CM_ "AUTOGENERATED FILE, DO NOT EDIT"

CM_ "bmw_e39_540i.dbc starts here"
Skip to content
Search or jump to…

Pull requests
Issues
Marketplace
Explore

@killinen
killinen
/
opendbc
forked from Sebastian9191/opendbc
0
0518
 Code
 Pull requests 0 Actions
 Projects 0
 Wiki
 Security 0
 Insights
 Settings
opendbc/BMW_E39.dbc
@killinen killinen OpenDBC updates
cff6fd5 2 days ago
@killinen@Sebastian9191
145 lines (122 sloc)  4.56 KB

VERSION ""

NS_ :

BS_:

BU_: XXX

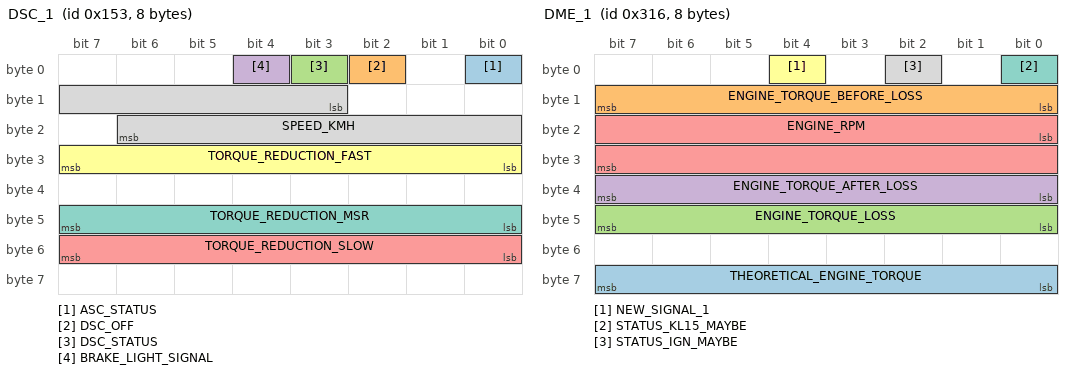
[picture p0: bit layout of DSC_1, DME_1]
BO_ 339 DSC_1: 8 XXX
 SG_ ASC_STATUS : 0|1@1+ (1,0) [0|3] "" XXX
 SG_ DSC_OFF : 2|1@1+ (1,0) [0|3] "" XXX
 SG_ DSC_STATUS : 3|1@0+ (1,0) [0|3] "" XXX
 SG_ BRAKE_LIGHT_SIGNAL : 4|1@0+ (1,0) [0|3] "" XXX
 SG_ TORQUE_REDUCTION_SLOW : 55|8@0+ (1,0) [0|255] "" XXX
 SG_ TORQUE_REDUCTION_FAST : 31|8@0+ (1,0) [0|255] "" XXX
 SG_ TORQUE_REDUCTION_MSR : 47|8@0+ (1,0) [0|255] "" XXX
 SG_ SPEED_KMH : 11|12@1+ (0.0625,-2.64) [0|1] "kmh" XXX

BO_ 501 SZL_1: 8 XXX
 SG_ STEERING_VELOCITY : 16|15@1- (0.045,0) [0|1] "" XXX
 SG_ STEERING_ANGLE : 0|15@1- (0.045,0) [0|1] "" XXX

BO_ 790 DME_1: 8 XXX
 SG_ THEORETICAL_ENGINE_TORQUE : 63|8@0+ (1,0) [0|65535] "" XXX
 SG_ ENGINE_TORQUE_BEFORE_LOSS : 8|8@1+ (1,0) [0|65535] "" XXX
 SG_ ENGINE_TORQUE_LOSS : 47|8@0+ (1,0) [0|255] "" XXX
 SG_ ENGINE_TORQUE_AFTER_LOSS : 39|8@0+ (1,0) [0|65535] "" XXX
 SG_ ENGINE_RPM : 16|16@1+ (0.15625,0) [0|65535] "" XXX
 SG_ NEW_SIGNAL_1 : 4|1@0+ (1,0) [0|3] "" XXX
 SG_ STATUS_KL15_MAYBE : 0|1@0+ (1,0) [0|1] "" XXX
 SG_ STATUS_IGN_MAYBE : 2|1@0+ (1,0) [0|1] "" XXX

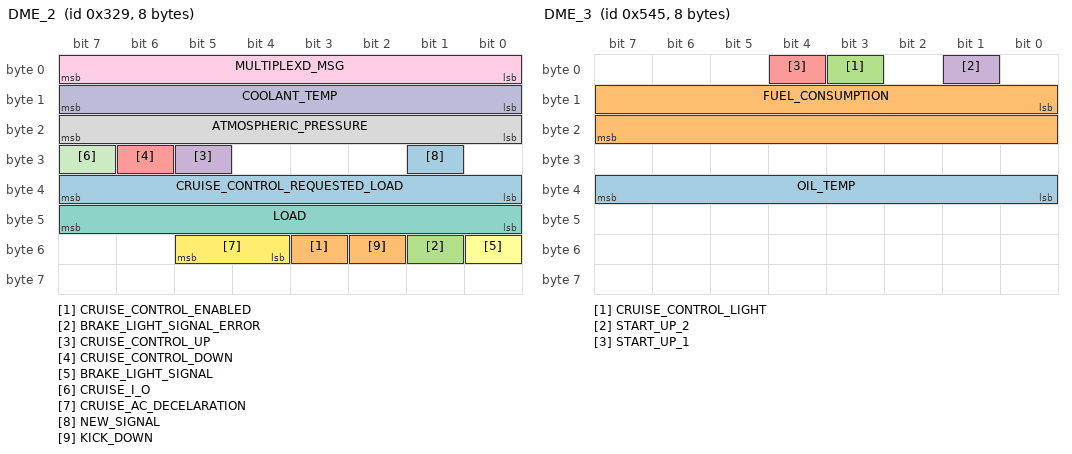
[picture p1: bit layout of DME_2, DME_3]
BO_ 809 DME_2: 8 XXX
 SG_ CRUISE_CONTROL_REQUESTED_LOAD : 39|8@0+ (1,0) [0|255] "" XXX
 SG_ CRUISE_CONTROL_ENABLED : 51|1@0+ (1,0) [0|1] "" XXX
 SG_ BRAKE_LIGHT_SIGNAL_ERROR : 49|1@0+ (1,0) [0|1] "" XXX
 SG_ CRUISE_CONTROL_UP : 29|1@0+ (1,0) [0|1] "" XXX
 SG_ CRUISE_CONTROL_DOWN : 30|1@0+ (1,0) [0|1] "" XXX
 SG_ BRAKE_LIGHT_SIGNAL : 48|1@0+ (1,0) [0|1] "" XXX
 SG_ LOAD : 47|8@0+ (1,0) [0|1] "nm" XXX
 SG_ ATMOSPHERIC_PRESSURE : 23|8@0+ (2,597) [0|255] "mbar" XXX
 SG_ MULTIPLEXD_MSG : 7|8@0+ (1,0) [0|255] "" XXX
 SG_ COOLANT_TEMP : 15|8@0+ (0.75,-48) [0|255] "" XXX
 SG_ CRUISE_I_O : 31|1@0+ (1,0) [0|1] "" XXX
 SG_ CRUISE_AC_DECELARATION : 53|2@0+ (1,0) [0|3] "" XXX
 SG_ NEW_SIGNAL : 25|1@1+ (1,0) [0|3] "" XXX
 SG_ KICK_DOWN : 50|1@0+ (1,0) [0|1] "" XXX

BO_ 1349 DME_3: 8 XXX
 SG_ OIL_TEMP : 39|8@0+ (1,-48) [0|255] "" XXX
 SG_ FUEL_CONSUMPTION : 8|16@1+ (1,0) [0|255] "" XXX
 SG_ CRUISE_CONTROL_LIGHT : 3|1@0+ (1,0) [0|1] "" XXX
 SG_ START_UP_2 : 1|1@0+ (1,0) [0|1] "" XXX
 SG_ START_UP_1 : 4|1@0+ (1,0) [0|1] "" XXX

BO_ 1555 IKE_1: 8 XXX
 SG_ FUEL_LEVEL : 23|8@0+ (1,0) [0|255] "" XXX
 SG_ MILAGE : 0|16@1+ (10,0) [0|65535] "" XXX

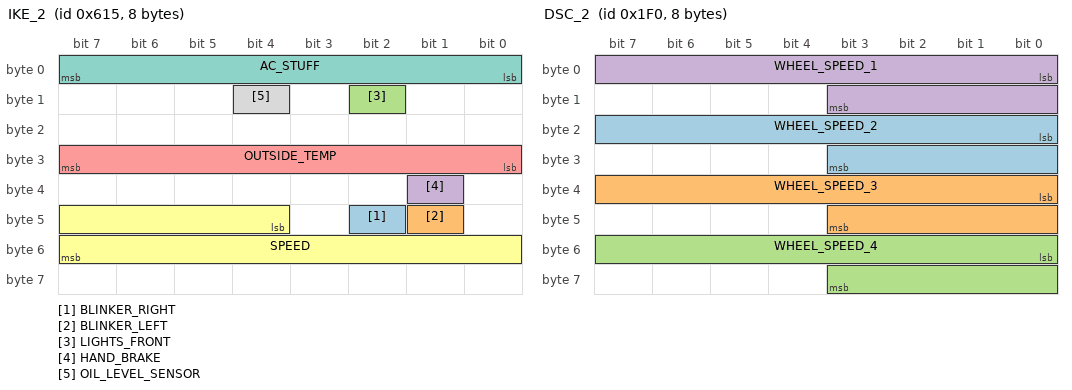
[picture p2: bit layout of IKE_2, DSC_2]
BO_ 1557 IKE_2: 8 XXX
 SG_ BLINKER_RIGHT : 42|1@1+ (1,0) [0|3] "" XXX
 SG_ BLINKER_LEFT : 41|1@1+ (1,0) [0|7] "" XXX
 SG_ LIGHTS_FRONT : 10|1@1+ (1,0) [0|3] "" XXX
 SG_ HAND_BRAKE : 33|1@1+ (1,0) [0|3] "" XXX
 SG_ OUTSIDE_TEMP : 31|8@0+ (1,0) [0|255] "°C" XXX
 SG_ SPEED : 44|12@1+ (0.11,0) [0|4095] "kph" XXX
 SG_ AC_STUFF : 7|8@0+ (1,0) [0|31] "" XXX
 SG_ OIL_LEVEL_SENSOR : 12|1@0+ (1,0) [0|1] "" XXX

BO_ 496 DSC_2: 8 XXX
 SG_ WHEEL_SPEED_2 : 16|12@1+ (0.06,0) [0|4095] "km/h" XXX
 SG_ WHEEL_SPEED_3 : 32|12@1+ (0.06,0) [0|4095] "km/h" XXX
 SG_ WHEEL_SPEED_4 : 48|12@1+ (0.06,0) [0|4095] "km/h" XXX
 SG_ WHEEL_SPEED_1 : 0|12@1+ (0.06,0) [0|4095] "km/h" XXX

BO_ 499 DSC_3: 8 XXX
 SG_ LATERAL_ACCELERATION : 0|16@1- (1,0) [0|65535] "" XXX
 SG_ LONGITUDINAL_ACCELERATION : 16|16@1- (1,0) [0|65535] "" XXX

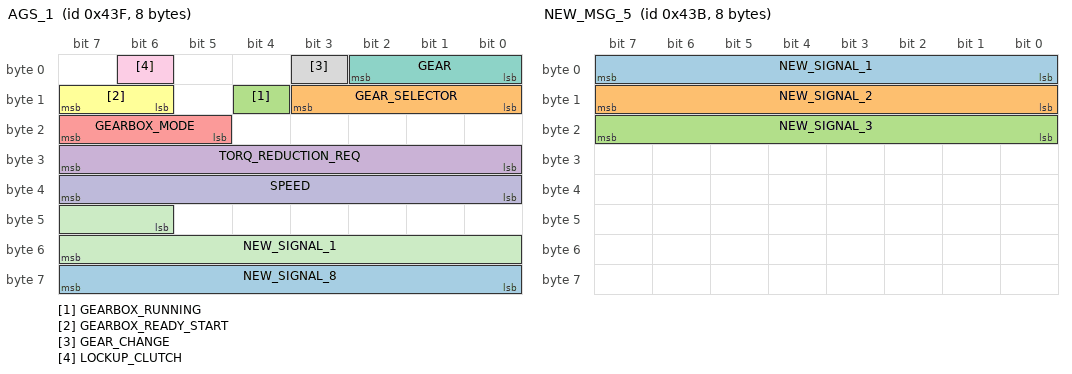
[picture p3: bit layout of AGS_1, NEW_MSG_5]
BO_ 1087 AGS_1: 8 XXX
 SG_ NEW_SIGNAL_8 : 63|8@0+ (1,0) [0|1] "" XXX
 SG_ GEAR_SELECTOR : 11|4@0+ (1,0) [0|1] "" XXX
 SG_ GEARBOX_RUNNING : 12|1@0+ (1,0) [0|3] "" XXX
 SG_ TORQ_REDUCTION_REQ : 31|8@0+ (1,0) [0|255] "" XXX
 SG_ GEARBOX_MODE : 23|3@0+ (1,0) [0|1] "" XXX
 SG_ GEARBOX_READY_START : 15|2@0+ (1,0) [0|1] "" XXX
 SG_ GEAR : 0|3@1+ (1,0) [0|7] "" XXX
 SG_ GEAR_CHANGE : 3|1@1+ (1,0) [0|7] "" XXX
 SG_ LOCKUP_CLUTCH : 6|1@0+ (1,0) [0|3] "" XXX
 SG_ SPEED : 39|8@0+ (1.37,0) [0|1] "" XXX
 SG_ NEW_SIGNAL_1 : 46|10@1+ (1,0) [0|255] "" XXX

BO_ 1916 NEW_MSG_2: 8 XXX
 SG_ ACCELEROMETER : 16|16@1- (1,0) [0|1] "" XXX

BO_ 1919 NEW_MSG_3: 8 XXX
 SG_ BRAKE_PRESSURE : 48|16@1+ (1,0) [0|65535] "" XXX

BO_ 1973 NEW_MSG_4: 8 XXX

BO_ 1083 NEW_MSG_5: 8 XXX
 SG_ NEW_SIGNAL_1 : 7|8@0+ (1,0) [0|1] "" XXX
 SG_ NEW_SIGNAL_2 : 15|8@0+ (1,0) [0|1] "" XXX
 SG_ NEW_SIGNAL_3 : 23|8@0+ (1,0) [0|1] "" XXX

CM_ SG_ 1349 START_UP_2 "Goes to zero right afer startup";
CM_ SG_ 1349 START_UP_1 "Goes to zero right after ignition activation";
CM_ SG_ 1555 FUEL_LEVEL "In liters";
CM_ SG_ 496 WHEEL_SPEED_2 "raw wheel speed";
CM_ SG_ 496 WHEEL_SPEED_3 "raw wheel speed";
CM_ SG_ 496 WHEEL_SPEED_4 "raw wheel speed";
CM_ SG_ 496 WHEEL_SPEED_1 "raw wheel speed";
© 2020 GitHub, Inc.
Terms
Privacy
Security
Status
Help
Contact GitHub
Pricing
API
Training
Blog
About
